# STM32N645 register map
File version: 1.0
CPU: CM55 r0p1, little endian, no MPU, FPU, vendor SysTick, 8 interrupt priority bits
Registers are 32-bit, read-write, reset 0x0 unless marked. A register's access mark holds for its fields unless they carry their own. Offsets are from the block's base; [hi:lo] are bit positions; {n}, {i} and the like mark numbered series; 'fields as' and 'values as' point back to an identical list.

## TIM2 — General-purpose timers
Base 0x40000000
Same registers: TIM2_S 0x50000000
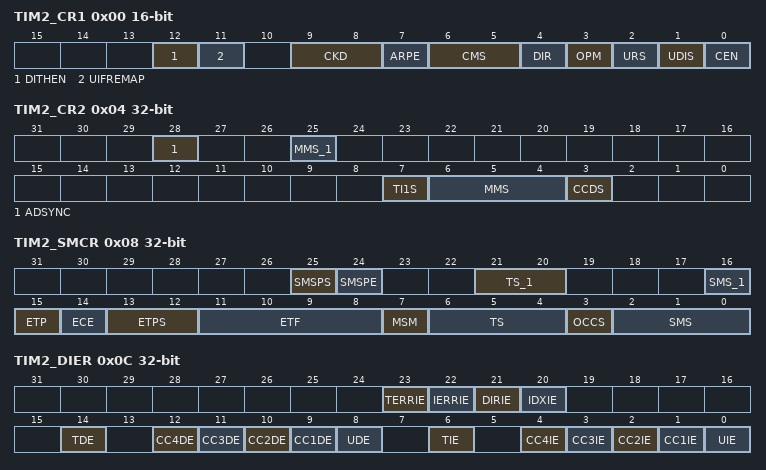
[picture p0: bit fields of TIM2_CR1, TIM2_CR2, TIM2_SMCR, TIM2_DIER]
0x00 TIM2_CR1 16-bit — TIM2 control register 1
  [12] DITHEN — Dithering Enable
    0=Dithering disabled; 1=Dithering enabled
  [11] UIFREMAP — UIF status bit remapping
    0=No remapping. UIF status bit is not copied to TIMx_CNT register bit 31.; 1=Remapping enabled. UIF status bit is copied to TIMx_CNT register bit 31.
  [9:8] CKD — Clock division
    0=t less than sub>DTS less than /sub> = t less than sub>tim_ker_ck less than /sub>; 1=t less than sub>DTS less than /sub> = 2 t less than sub>tim_ker_ck less than /sub>; 2=t less than sub>DTS less than /sub> = 4 t less than sub>tim_ker_ck less than /sub>
  [7] ARPE — Auto-reload preload enable
    0=TIMx_ARR register is not buffered; 1=TIMx_ARR register is buffered
  [6:5] CMS — Center-aligned mode selection
    0=Edge-aligned mode. The counter counts up or down depending on the direction bit (DIR).; 1=Center-aligned mode 1. The counter counts up and down alternatively. Output compare interrupt flags of channels configured in output (CCxS=00 in TIMx_CCMRx register) are set only when the counter is counting down.; 2=Center-aligned mode 2. The counter counts up and down alternatively. Output compare interrupt flags of channels configured in output (CCxS=00 in TIMx_CCMRx register) are set only when the counter is counting up.; 3=Center-aligned mode 3. The counter counts up and down alternatively. Output compare interrupt flags of channels configured in output (CCxS=00 in TIMx_CCMRx register) are set both when the counter is counting up or down.
  [4] DIR — Direction
    0=Counter used as upcounter; 1=Counter used as downcounter
  [3] OPM — One-pulse mode
    0=Counter is not stopped at update event; 1=Counter stops counting at the next update event (clearing the bit CEN)
  [2] URS — Update request source
    0=Any of the following events generate an update interrupt or DMA request if enabled. These events can be:; 1=Only counter overflow/underflow generates an update interrupt or DMA request if enabled
  [1] UDIS — Update disable
    0=UEV enabled. The Update (UEV) event is generated by one of the following events:; 1=UEV disabled. The Update event is not generated, shadow registers keep their value (ARR, PSC, CCRx). However the counter and the prescaler are reinitialized if the UG bit is set or if a hardware reset is received from the slave mode controller.
  [0] CEN — Counter enable
    0=Counter disabled; 1=Counter enabled
0x04 TIM2_CR2 — TIM2 control register 2
  [28] ADSYNC — ADC synchronization
    0=The timer operates independently from the ADC; 1=The timer operation is synchronized with the ADC clock to provide jitter-free sampling point. This mode can be enabled only with specific ADC / timer clock relationship. Refer to Section 54.4.25 for requirements.
  [25] MMS_1 — MMS[3]
  [7] TI1S — tim_ti1 selection
    0=The tim_ti1_in[15:0] multiplexer output is to tim_ti1 input; 1=The tim_ti1_in[15:0], tim_ti2_in[15:0] and tim_ti3_in[15:0] multiplexers outputs are XORed and connected to the tim_ti1 input. See also Section 53.3.29: Interfacing with Hall sensors on page 2562.
  [6:4] MMS — MMS[0]: Master mode selection
    0=Reset - the UG bit from the TIMx_EGR register is used as trigger output (tim_trgo). If the reset is generated by the trigger input (slave mode controller configured in reset mode) then the signal on tim_trgo is delayed compared to the actual reset.; 1=Enable - the Counter enable signal, CNT_EN, is used as trigger output (tim_trgo). It is useful to start several timers at the same time or to control a window in which a slave timer is enabled. The Counter Enable signal is generated by a logic AND between CEN control bit and the trigger input when configured in gated mode.; 2=Update - The update event is selected as trigger output (tim_trgo). For instance a master timer can then be used as a prescaler for a slave timer.; 3=Compare Pulse - The trigger output send a positive pulse when the CC1IF flag is to be set (even if it was already high), as soon as a capture or a compare match occurred (tim_trgo); {v}=Compare - tim_oc{v-3}refc signal is used as trigger output (tim_trgo) (v=4..7)
  [3] CCDS — Capture/compare DMA selection
    0=CCx DMA request sent when CCx event occurs; 1=CCx DMA requests sent when update event occurs
0x08 TIM2_SMCR — TIM2 slave mode control register
  [25] SMSPS — SMS preload source
    0=The transfer is triggered by the Timer's Update event; 1=The transfer is triggered by the Index event
  [24] SMSPE — SMS preload enable
    0=SMS[3:0] bitfield is not preloaded; 1=SMS[3:0] preload is enabled
  [21:20] TS_1 — TS[4:3]
  [16] SMS_1 — SMS[3]
  [15] ETP — External trigger polarity
    0=tim_etr_in is non-inverted, active at high level or rising edge; 1=tim_etr_in is inverted, active at low level or falling edge
  [14] ECE — External clock enable
    0=External clock mode 2 disabled; 1=External clock mode 2 enabled. The counter is clocked by any active edge on the tim_etrf signal.
  [13:12] ETPS — External trigger prescaler
    0=Prescaler OFF; 1=tim_etrp frequency divided by 2; 2=tim_etrp frequency divided by 4; 3=tim_etrp frequency divided by 8
  [11:8] ETF — External trigger filter
    0=No filter, sampling is done at f less than sub>DTS less than /sub>; 1=f less than sub>SAMPLING less than /sub>=f less than sub>tim_ker_ck less than /sub>, N=2; 2=f less than sub>SAMPLING less than /sub>=f less than sub>tim_ker_ck less than /sub>, N=4; 3=f less than sub>SAMPLING less than /sub>=f less than sub>tim_ker_ck less than /sub>, N=8; 4=f less than sub>SAMPLING less than /sub>=f less than sub>DTS less than /sub>/2, N=6; 5=f less than sub>SAMPLING less than /sub>=f less than sub>DTS less than /sub>/2, N=8; 6=f less than sub>SAMPLING less than /sub>=f less than sub>DTS less than /sub>/4, N=6; 7=f less than sub>SAMPLING less than /sub>=f less than sub>DTS less than /sub>/4, N=8; 8=f less than sub>SAMPLING less than /sub>=f less than sub>DTS less than /sub>/8, N=6; 9=f less than sub>SAMPLING less than /sub>=f less than sub>DTS less than /sub>/8, N=8; 10=f less than sub>SAMPLING less than /sub>=f less than sub>DTS less than /sub>/16, N=5; 11=f less than sub>SAMPLING less than /sub>=f less than sub>DTS less than /sub>/16, N=6; 12=f less than sub>SAMPLING less than /sub>=f less than sub>DTS less than /sub>/16, N=8; 13=f less than sub>SAMPLING less than /sub>=f less than sub>DTS less than /sub>/32, N=5; 14=f less than sub>SAMPLING less than /sub>=f less than sub>DTS less than /sub>/32, N=6; 15=f less than sub>SAMPLING less than /sub>=f less than sub>DTS less than /sub>/32, N=8
  [7] MSM — Master/Slave mode
    0=No action; 1=The effect of an event on the trigger input (tim_trgi) is delayed to allow a perfect synchronization between the current timer and its slaves (through tim_trgo). It is useful if we want to synchronize several timers on a single external event.
  [6:4] TS — TS[0]: Trigger selection
    {v}=Internal trigger {v} (tim_itr{v}) (v=0..3); 4=tim_ti1 edge detector (tim_ti1f_ed); 5=Filtered timer input 1 (tim_ti1fp1); 6=Filtered timer input 2 (tim_ti2fp2); 7=External trigger input (tim_etrf)
  [3] OCCS — OCREF clear selection
    0=tim_ocref_clr_int is connected to the tim_ocref_clr input; 1=tim_ocref_clr_int is connected to tim_etrf
  [2:0] SMS — SMS[0]: Slave mode selection
    0=Slave mode disabled - if CEN = 1 then the prescaler is clocked directly by the internal clock; 1=Encoder mode 1 - Counter counts up/down on tim_ti1fp1 edge depending on tim_ti2fp2 level; 2=Encoder mode 2 - Counter counts up/down on tim_ti2fp2 edge depending on tim_ti1fp1 level; 3=Encoder mode 3 - Counter counts up/down on both tim_ti1fp1 and tim_ti2fp2 edges depending on the level of the other input; 4=Reset Mode - Rising edge of the selected trigger input (tim_trgi) reinitializes the counter and generates an update of the registers; 5=Gated Mode - The counter clock is enabled when the trigger input (tim_trgi) is high. The counter stops (but is not reset) as soon as the trigger becomes low. Both start and stop of the counter are controlled.; 6=Trigger Mode - The counter starts at a rising edge of the trigger tim_trgi (but it is not reset). Only the start of the counter is controlled.; 7=External Clock Mode 1 - Rising edges of the selected trigger (tim_trgi) clock the counter
0x0C TIM2_DIER — TIM2 DMA/Interrupt enable register
  [23] TERRIE — Transition error interrupt enable
    0=Transition error interrupt disabled; 1=Transition error interrupt enabled
  [22] IERRIE — Index error interrupt enable
    0=Index error interrupt disabled; 1=Index error interrupt enabled
  [21] DIRIE — Direction change interrupt enable
    0=Direction change interrupt disabled; 1=Direction change interrupt enabled
  [20] IDXIE — Index interrupt enable
    0=Index interrupt disabled; 1=Index interrupt enabled
  [14] TDE — Trigger DMA request enable
    0=Trigger DMA request disabled; 1=Trigger DMA request enabled
  [n+8] CC{n}DE (n=1..4) — Capture/Compare {n} DMA request enable
    0=CC{n} DMA request disabled; 1=CC{n} DMA request enabled
  [8] UDE — Update DMA request enable
    0=Update DMA request disabled; 1=Update DMA request enabled
  [6] TIE — Trigger interrupt enable
    0=Trigger interrupt disabled; 1=Trigger interrupt enabled
  [n] CC{n}IE (n=1..4) — Capture/Compare {n} interrupt enable
    0=CC{n} interrupt disabled; 1=CC{n} interrupt enabled
  [0] UIE — Update interrupt enable
    0=Update interrupt disabled; 1=Update interrupt enabled
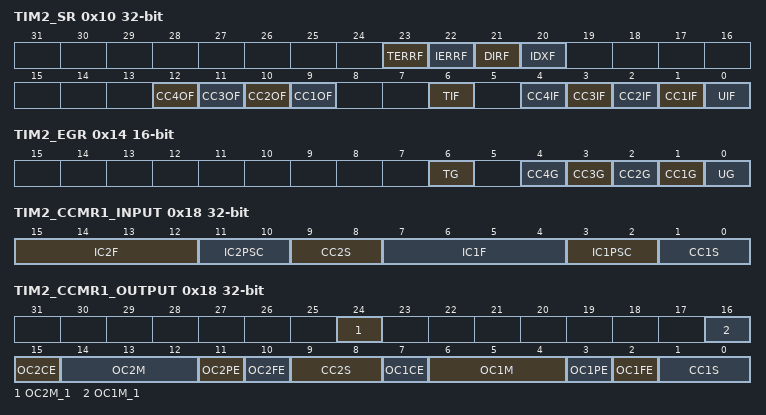
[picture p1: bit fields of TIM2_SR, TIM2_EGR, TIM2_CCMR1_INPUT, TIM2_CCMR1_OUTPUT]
0x10 TIM2_SR — TIM2 status register
  [23] TERRF — Transition error interrupt flag
    0=No encoder transition error has been detected; 1=An encoder transition error has been detected
  [22] IERRF — Index error interrupt flag
    0=No index error has been detected; 1=An index error has been detected
  [21] DIRF — Direction change interrupt flag
    0=No direction change; 1=Direction change
  [20] IDXF — Index interrupt flag
    0=No index event occurred; 1=An index event has occurred
  [12] CC4OF — Capture/Compare 4 overcapture flag
  [11] CC3OF — Capture/Compare 3 overcapture flag
  [10] CC2OF — Capture/compare 2 overcapture flag
  [9] CC1OF — Capture/Compare 1 overcapture flag
    0=No overcapture has been detected; 1=The counter value has been captured in TIMx_CCR1 register while CC1IF flag was already set
  [6] TIF — Trigger interrupt flag
    0=No trigger event occurred; 1=Trigger interrupt pending
  [4] CC4IF — Capture/Compare 4 interrupt flag
  [3] CC3IF — Capture/Compare 3 interrupt flag
  [2] CC2IF — Capture/Compare 2 interrupt flag
  [1] CC1IF — Capture/compare 1 interrupt flag
    0=No compare match / No input capture occurred; 1=A compare match or an input capture occurred
  [0] UIF — Update interrupt flag
    0=No update occurred; 1=Update interrupt pending. This bit is set by hardware when the registers are updated:
0x14 TIM2_EGR 16-bit wo — TIM2 event generation register
  [6] TG — Trigger generation
    0=No action; 1=The TIF flag is set in TIMx_SR register. Related interrupt or DMA transfer can occur if enabled.
  [4] CC4G — Capture/compare 4 generation
  [3] CC3G — Capture/compare 3 generation
  [2] CC2G — Capture/compare 2 generation
  [1] CC1G — Capture/compare 1 generation
    0=No action; 1=A capture/compare event is generated on channel 1:
  [0] UG — Update generation
    0=No action; 1=Re-initialize the counter and generates an update of the registers. Note that the prescaler counter is cleared too (anyway the prescaler ratio is not affected). The counter is cleared if the center-aligned mode is selected or if DIR=0 (upcounting), else it takes the auto-reload value (TIMx_ARR) if DIR=1 (downcounting).
0x18 TIM2_CCMR1_INPUT — TIM2 capture/compare mode register 1
  [15:12] IC2F — Input capture 2 filter
  [11:10] IC2PSC — Input capture 2 prescaler
  [9:8] CC2S — Capture/compare 2 selection
    0=CC2 channel is configured as output; 1=CC2 channel is configured as input, tim_ic2 is mapped on tim_ti2; 2=CC2 channel is configured as input, tim_ic2 is mapped on tim_ti1; 3=CC2 channel is configured as input, tim_ic2 is mapped on tim_trc. This mode is working only if an internal trigger input is selected through TS bit (TIMx_SMCR register)
  [7:4] IC1F — Input capture 1 filter
    values as TIM2_SMCR.ETF
  [3:2] IC1PSC — Input capture 1 prescaler
    0=no prescaler, capture is done each time an edge is detected on the capture input; 1=capture is done once every 2 events; 2=capture is done once every 4 events; 3=capture is done once every 8 events
  [1:0] CC1S — Capture/Compare 1 selection
    0=CC1 channel is configured as output; 1=CC1 channel is configured as input, tim_ic1 is mapped on tim_ti1; 2=CC1 channel is configured as input, tim_ic1 is mapped on tim_ti2; 3=CC1 channel is configured as input, tim_ic1 is mapped on tim_trc. This mode is working only if an internal trigger input is selected through TS bit (TIMx_SMCR register)
0x18 TIM2_CCMR1_OUTPUT (alternate view of TIM2_CCMR1_INPUT) — TIM2 capture/compare mode register 1
  [24] OC2M_1 — OC2M[3]
  [16] OC1M_1 — OC1M[3]
  [15] OC2CE — Output compare 2 clear enable
  [14:12] OC2M — OC2M[2:0]: Output compare 2 mode
  [11] OC2PE — Output compare 2 preload enable
  [10] OC2FE — Output compare 2 fast enable
  [9:8] CC2S — Capture/Compare 2 selection
    0=CC2 channel is configured as output; 1=CC2 channel is configured as input, tim_ic2 is mapped on tim_ti2; 2=CC2 channel is configured as input, tim_ic2 is mapped on tim_ti1; 3=CC2 channel is configured as input, tim_ic2 is mapped on tim_trc. This mode is working only if an internal trigger input is selected through the TS bit (TIMx_SMCR register)
  [7] OC1CE — Output compare 1 clear enable
    0=tim_oc1ref is not affected by the tim_ocref_clr_int input; 1=tim_oc1ref is cleared as soon as a High level is detected on tim_ocref_clr_int input
  [6:4] OC1M — OC1M[2:0]: Output compare 1 mode
    0=Frozen - The comparison between the output compare register TIMx_CCR1 and the counter TIMx_CNT has no effect on the outputs. This mode can be used when the timer serves as a software timebase. When the frozen mode is enabled during timer operation, the ouput keeps the state (active or inactive) it had before entering the frozen state.; 1=Set channel 1 to active level on match. tim_oc1ref signal is forced high when the counter TIMx_CNT matches the capture/compare register 1 (TIMx_CCR1).; 2=Set channel 1 to inactive level on match. tim_oc1ref signal is forced low when the counter TIMx_CNT matches the capture/compare register 1 (TIMx_CCR1).; 3=Toggle - tim_oc1ref toggles when TIMx_CNT=TIMx_CCR1; 4=Force inactive level - tim_oc1ref is forced low; 5=Force active level - tim_oc1ref is forced high; 6=PWM mode 1 - In upcounting, channel 1 is active as long as TIMx_CNT less than TIMx_CCR1 else inactive. In downcounting, channel 1 is inactive (tim_oc1ref=0) as long as TIMx_CNT>TIMx_CCR1 else active (tim_oc1ref=1).; 7=PWM mode 2 - In upcounting, channel 1 is inactive as long as TIMx_CNT less than TIMx_CCR1 else active. In downcounting, channel 1 is active as long as TIMx_CNT>TIMx_CCR1 else inactive.
  [3] OC1PE — Output compare 1 preload enable
    0=Preload register on TIMx_CCR1 disabled. TIMx_CCR1 can be written at anytime, the new value is taken in account immediately.; 1=Preload register on TIMx_CCR1 enabled. Read/Write operations access the preload register. TIMx_CCR1 preload value is loaded in the active register at each update event.
  [2] OC1FE — Output compare 1 fast enable
    0=CC1 behaves normally depending on counter and CCR1 values even when the trigger is ON. The minimum delay to activate CC1 output when an edge occurs on the trigger input is 5 clock cycles.; 1=An active edge on the trigger input acts like a compare match on CC1 output. Then, OC is set to the compare level independently from the result of the comparison. Delay to sample the trigger input and to activate CC1 output is reduced to 3 clock cycles. OCFE acts only if the channel is configured in PWM1 or PWM2 mode.
  [1:0] CC1S — Capture/Compare 1 selection
    values as TIM2_CCMR1_INPUT.CC1S
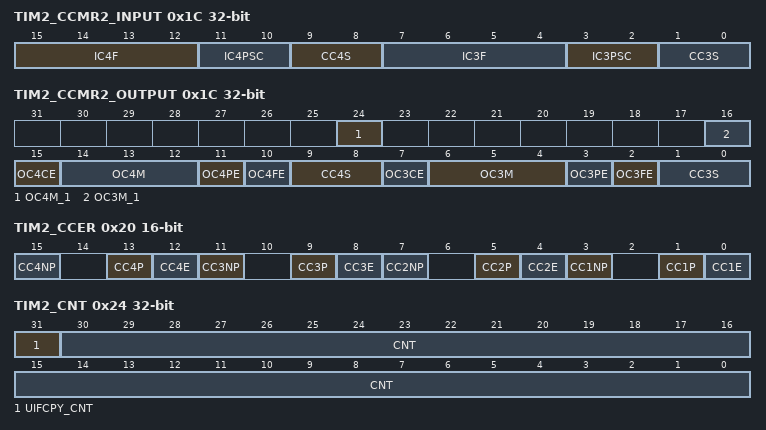
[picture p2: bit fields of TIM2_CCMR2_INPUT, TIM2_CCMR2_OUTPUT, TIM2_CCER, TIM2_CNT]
0x1C TIM2_CCMR2_INPUT — TIM2 capture/compare mode register 2
  [15:12] IC4F — Input capture 4 filter
  [11:10] IC4PSC — Input capture 4 prescaler
  [9:8] CC4S — Capture/Compare 4 selection
    0=CC4 channel is configured as output; 1=CC4 channel is configured as input, tim_ic4 is mapped on tim_ti4; 2=CC4 channel is configured as input, tim_ic4 is mapped on tim_ti3; 3=CC4 channel is configured as input, tim_ic4 is mapped on tim_trc. This mode is working only if an internal trigger input is selected through TS bit (TIMx_SMCR register)
  [7:4] IC3F — Input capture 3 filter
  [3:2] IC3PSC — Input capture 3 prescaler
  [1:0] CC3S — Capture/Compare 3 selection
    0=CC3 channel is configured as output; 1=CC3 channel is configured as input, tim_ic3 is mapped on tim_ti3; 2=CC3 channel is configured as input, tim_ic3 is mapped on tim_ti4; 3=CC3 channel is configured as input, tim_ic3 is mapped on tim_trc. This mode is working only if an internal trigger input is selected through TS bit (TIMx_SMCR register)
0x1C TIM2_CCMR2_OUTPUT (alternate view of TIM2_CCMR2_INPUT) — TIM2 capture/compare mode register 2
  [24] OC4M_1 — OC4M[3]
  [16] OC3M_1 — OC3M[3]
  [15] OC4CE — Output compare 4 clear enable
  [14:12] OC4M — OC4M[2:0]: Output compare 4 mode
  [11] OC4PE — Output compare 4 preload enable
  [10] OC4FE — Output compare 4 fast enable
  [9:8] CC4S — Capture/Compare 4 selection
    values as TIM2_CCMR2_INPUT.CC4S
  [7] OC3CE — Output compare 3 clear enable
  [6:4] OC3M — OC3M[2:0]: Output compare 3 mode
  [3] OC3PE — Output compare 3 preload enable
  [2] OC3FE — Output compare 3 fast enable
  [1:0] CC3S — Capture/Compare 3 selection
    values as TIM2_CCMR2_INPUT.CC3S
0x20 TIM2_CCER 16-bit — TIM2 capture/compare enable register
  [4n-1] CC{n}NP (n=1..4) — Capture/Compare {n} output Polarity.
  [13] CC4P — Capture/Compare 4 output Polarity.
  [12] CC4E — Capture/Compare 4 output enable.
  [9] CC3P — Capture/Compare 3 output Polarity.
  [8] CC3E — Capture/Compare 3 output enable.
  [5] CC2P — Capture/Compare 2 output Polarity.
  [4] CC2E — Capture/Compare 2 output enable.
  [1] CC1P — Capture/Compare 1 output Polarity.
    0=OC1 active high (output mode) / Edge sensitivity selection (input mode, see below); 1=OC1 active low (output mode) / Edge sensitivity selection (input mode, see below)
  [0] CC1E — Capture/Compare 1 output enable.
    0=Capture mode disabled / OC1 is not active; 1=Capture mode enabled / OC1 signal is output on the corresponding output pin
0x24 TIM2_CNT — TIM2 counter
  [31] UIFCPY_CNT — Value depends on IUFREMAP in TIMx_CR1.
  [30:0] CNT — Least significant part of counter value
0x28 TIM2_PSC 16-bit — TIM2 prescaler
  [15:0] PSC — Prescaler value
0x2C TIM2_ARR reset 0xFFFFFFFF — TIM2 auto-reload register
  [31:0] ARR — Auto-reload value
{0x30+4i} TIM2_CCR{i} (i=1..4) — TIM2 capture/compare register {i}
  [31:0] CCR{i} — Capture/compare {i} value
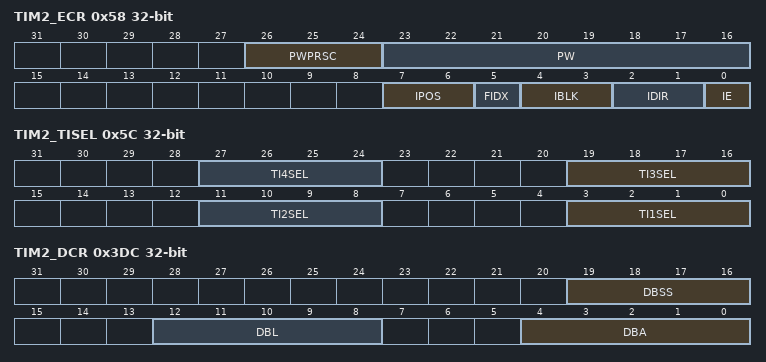
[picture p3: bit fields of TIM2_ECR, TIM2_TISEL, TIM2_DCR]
0x58 TIM2_ECR — TIM2 timer encoder control register
  [26:24] PWPRSC — Pulse width prescaler
  [23:16] PW — Pulse width
  [7:6] IPOS — Index positioning
    0=Index resets the counter when AB = 00; 1=Index resets the counter when AB = 01; 2=Index resets the counter when AB = 10; 3=Index resets the counter when AB = 11
  [5] FIDX — First index
    0=Index is always active; 1=the first Index only resets the counter
  [4:3] IBLK — Index blanking
    0=Index always active; 1=Index disabled hen tim_ti3 input is active, as per CC3P bitfield; 2=Index disabled when tim_ti4 input is active, as per CC4P bitfield
  [2:1] IDIR — Index direction
    0=Index resets the counter whatever the direction; 1=Index resets the counter when up-counting only; 2=Index resets the counter when down-counting only
  [0] IE — Index enable
    0=Index disabled; 1=Index enabled
0x5C TIM2_TISEL — TIM2 timer input selection register
  [8n-5:8n-8] TI{n}SEL (n=1..4) — Selects tim_ti{n}[15:0] input
    0=tim_ti{n}_in0: TIMx_CH{n}; 1=tim_ti{n}_in1; 15=tim_ti{n}_in15
0x60 TIM2_AF1 — TIM2 alternate function register 1
  [17:14] ETRSEL — etr_in source selection
    0=tim_etr0: TIMx_ETR input; 1=tim_etr1; 15=tim_etr15
0x64 TIM2_AF2 — TIM2 alternate function register 2
  [18:16] OCRSEL — ocref_clr source selection
    0=tim_ocref_clr0; 1=tim_ocref_clr1; 7=tim_ocref_clr7
0x3DC TIM2_DCR — TIM2 DMA control register
  [19:16] DBSS — DMA burst source selection
    1=Update; {v}=CC{v-1} (v=2..5); 6=COM; 7=Trigger
  [12:8] DBL — DMA burst length
    0=1 transfer; 1=2 transfers; 2=3 transfers; 26=26 transfers
  [4:0] DBA — DMA base address
    0=TIMx_CR1,; 1=TIMx_CR2,; 2=TIMx_SMCR,
0x3E0 TIM2_DMAR — TIM2 DMA address for full transfer
  [31:0] DMAB — DMA register for burst accesses

## TIM3 — General purpose timers
Base 0x40000400
Same registers: TIM3_S 0x50000400
Registers as TIM2 (with TIM2 read as TIM3).

## TIM4 — General purpose timers
Base 0x40000800
Same registers: TIM4_S 0x50000800
Registers as TIM2 (with TIM2 read as TIM4).

## TIM5 — General purpose timers
Base 0x40000C00
Same registers: TIM5_S 0x50000C00
Registers as TIM2 (with TIM2 read as TIM5).
